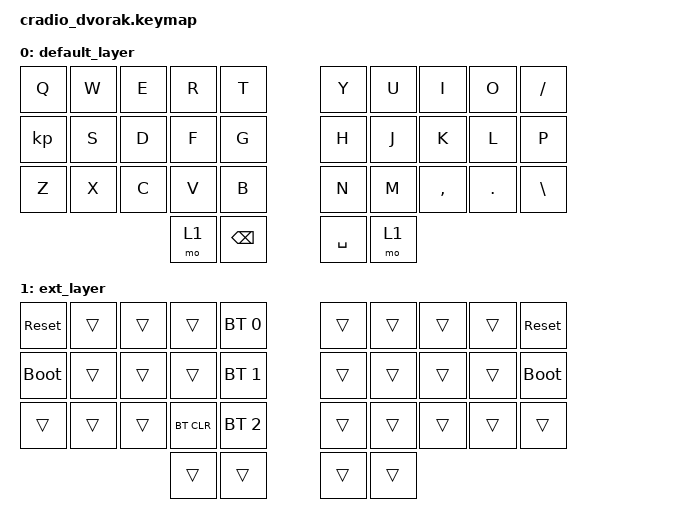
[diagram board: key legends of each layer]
// Copyright (c) 2022 The ZMK Contributors
// SPDX-License-Identifier: MIT

#include <behaviors.dtsi>
#include <dt-bindings/zmk/keys.h>
#include <dt-bindings/zmk/bt.h>

// Home row mods macro

#define DEFAULT 0


&lt {
    flavor = "tap-preferred";
    tapping-term-ms = <200>;
    quick-tap-ms = <200>;
};

/ {
    behaviors {
        ht: hold_tap {
            compatible = "zmk,behavior-hold-tap";
            #binding-cells = <2>;
            flavor = "tap-preferred";
            tapping-term-ms = <200>;
            quick-tap-ms = <200>;
            require-prior-idle-ms = <100>;
            bindings = <&kp>, <&kp>;
        };
    };

/*
    conditional_layers {
        compatible = "zmk,conditional-layers";
        tri_layer {
            if-layers = <NAV NUMS>;
            then-layer = <SYSTEM>;
        };
    }; 
    */

    keymap {
        compatible = "zmk,keymap";


        default_layer {
            bindings = <
        //╭──────────┬──────────┬──────────┬──────────┬──────────╮   ╭──────────┬──────────┬──────────┬──────────┬──────────╮
        //│  Q       │  W       │  E       │  R       │  T       │   │  Y       │  U       │  I       │  O       │ - _      │
            &kp Q      &kp W      &kp E      &kp R      &kp T          &kp Y      &kp U      &kp I      &kp O      &kp FSLH
        //├──────────┼──────────┼──────────┼──────────┼──────────┤   ├──────────┼──────────┼──────────┼──────────┼──────────┤
        //│  A       │  S       │  D       │  F       │  G       │   │  H       │  J       │  K       │  L       │ P        │
            &kp        &kp S      &kp D      &kp F      &kp G          &kp H      &kp J      &kp K      &kp L      &kp P
        //├──────────┼──────────┼──────────┼──────────┼──────────┤   ├──────────┼──────────┼──────────┼──────────┼──────────┤
        //│  Z       │  X       │  C       │  V       │  B       │   │  N       │  M       │ , <      │ . >      │ # '      │
            &kp Z      &kp X      &kp C      &kp V      &kp B          &kp N      &kp M      &kp COMMA  &kp DOT    &kp BSLH
        //╰──────────┴──────────┴──────────┼──────────┼──────────┤   ├──────────┼──────────┼──────────┴──────────┴──────────╯
                                             &mo 1    &kp BSPC         &kp SPACE  &mo 1
        //                                 ╰──────────┴──────────╯   ╰──────────┴──────────╯
            >;
        };

        ext_layer {
            bindings = <
        //╭──────────┬──────────┬──────────┬──────────┬──────────╮   ╭──────────┬──────────┬──────────┬──────────┬──────────╮
        //│ RESET    │          │          │          │PROFILE 0 │   │          │          │          │          │  RESET   │
           &sys_reset  &trans     &trans     &trans    &bt BT_SEL 0    &trans     &trans     &trans     &trans    &sys_reset
        //├──────────┼──────────┼──────────┼──────────┼──────────┤   ├──────────┼──────────┼──────────┼──────────┼──────────┤
        //│BOOTLOADER│          │          │          │PROFILE 1 │   │          │          │          │          │BOOTLOADER│
          &bootloader  &trans     &trans     &trans   &bt BT_SEL 1    &trans     &trans     &trans     &trans    &bootloader
        //├──────────┼──────────┼──────────┼──────────┼──────────┤   ├──────────┼──────────┼──────────┼──────────┼──────────┤
        //│          │          │          │ CLEAR BT │PROFILE 2 │   │          │          │          │          │          │
            &trans     &trans     &trans    &bt BT_CLR &bt BT_SEL 2    &trans     &trans     &trans     &trans     &trans
        //╰──────────┴──────────┴──────────┼──────────┼──────────┤   ├──────────┼──────────┼──────────┴──────────┴──────────╯
                                             &trans     &trans         &trans     &trans
        //                                 ╰──────────┴──────────╯   ╰──────────┴──────────╯
            >;
        };


    };
};
